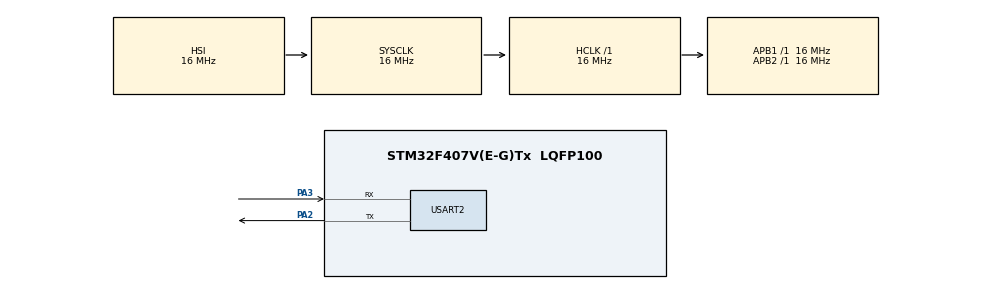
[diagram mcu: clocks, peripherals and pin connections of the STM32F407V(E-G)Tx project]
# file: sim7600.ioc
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FREERTOS.Tasks01=defaultTask,0,128,StartDefaultTask,Default,NULL,Dynamic,NULL,NULL
Mcu.Family=STM32F4
Mcu.Name=STM32F407V(E-G)Tx
Mcu.Package=LQFP100
NVIC.PriorityGroup=NVIC_PRIORITYGROUP_4
NVIC.TIM1_UP_TIM10_IRQn=true\:0\:0\:false\:false\:true\:false\:false\:true
NVIC.TimeBase=TIM1_UP_TIM10_IRQn
NVIC.TimeBaseIP=TIM1
NVIC.USART2_IRQn=true\:0\:0\:false\:false\:true\:false\:true\:true
PA13.Mode=Serial_Wire
PA13.Signal=SYS_JTMS-SWDIO
PA14.Mode=Serial_Wire
PA14.Signal=SYS_JTCK-SWCLK
PA2.Mode=Asynchronous
PA2.Signal=USART2_TX
PA3.Mode=Asynchronous
PA3.Signal=USART2_RX
PH0-OSC_IN.Mode=HSE-External-Oscillator
PH0-OSC_IN.Signal=RCC_OSC_IN
PH1-OSC_OUT.Mode=HSE-External-Oscillator
PH1-OSC_OUT.Signal=RCC_OSC_OUT
ProjectManager.HeapSize=0x200
ProjectManager.StackSize=0x400
ProjectManager.TargetToolchain=STM32CubeIDE
RCC.AHBFreq_Value=16000000
RCC.APB1Freq_Value=16000000
RCC.APB2Freq_Value=16000000
RCC.CortexFreq_Value=16000000
RCC.HSE_VALUE=25000000
RCC.HSI_VALUE=16000000
RCC.LSE_VALUE=32768
RCC.SYSCLKFreq_VALUE=16000000
RCC.VCOOutputFreq_Value=192000000
USART2.VirtualMode=VM_ASYNC
VP_FREERTOS_VS_CMSIS_V1.Mode=CMSIS_V1
VP_SYS_VS_tim1.Mode=TIM1
board=custom

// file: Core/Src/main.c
/* USER CODE BEGIN Header */
/**
  ******************************************************************************
  * @file           : main.c
  * @brief          : Main program body
  ******************************************************************************
  * @attention
  *
  * <h2><center>&copy; Copyright (c) 2021 STMicroelectronics.
  * All rights reserved.</center></h2>
  *
  * This software component is licensed by ST under BSD 3-Clause license,
  * the "License"; You may not use this file except in compliance with the
  * License. You may obtain a copy of the License at:
  *                        opensource.org/licenses/BSD-3-Clause
  *
  ******************************************************************************
  */
/* USER CODE END Header */
#include "main.h"
#include "cmsis_os.h"

UART_HandleTypeDef huart2;

osThreadId defaultTaskHandle;

void SystemClock_Config(void);
static void MX_GPIO_Init(void);
static void MX_USART2_UART_Init(void);
void StartDefaultTask(void const * argument);

int main(void)
{

  /* MCU Configuration--------------------------------------------------------*/

  /* Reset of all peripherals, Initializes the Flash interface and the Systick. */
  HAL_Init();

  /* Configure the system clock */
  SystemClock_Config();

  /* Initialize all configured peripherals */
  MX_GPIO_Init();
  MX_USART2_UART_Init();

  /* Create the thread(s) */
  /* definition and creation of defaultTask */
  __HAL_UART_ENABLE_IT(&huart2, UART_IT_RXNE);
  MX_FREERTOS_Init();

  /* Start scheduler */
  osKernelStart();

  /* We should never get here as control is now taken by the scheduler */
  /* Infinite loop */
  while (1)
  {

  }
}

void SystemClock_Config(void)
{
  RCC_OscInitTypeDef RCC_OscInitStruct = {0};
  RCC_ClkInitTypeDef RCC_ClkInitStruct = {0};

  /** Configure the main internal regulator output voltage
  */
  __HAL_RCC_PWR_CLK_ENABLE();
  __HAL_PWR_VOLTAGESCALING_CONFIG(PWR_REGULATOR_VOLTAGE_SCALE1);
  /** Initializes the RCC Oscillators according to the specified parameters
  * in the RCC_OscInitTypeDef structure.
  */
  RCC_OscInitStruct.OscillatorType = RCC_OSCILLATORTYPE_HSI;
  RCC_OscInitStruct.HSIState = RCC_HSI_ON;
  RCC_OscInitStruct.HSICalibrationValue = RCC_HSICALIBRATION_DEFAULT;
  RCC_OscInitStruct.PLL.PLLState = RCC_PLL_NONE;
  if (HAL_RCC_OscConfig(&RCC_OscInitStruct) != HAL_OK)
  {
    Error_Handler();
  }
  /** Initializes the CPU, AHB and APB buses clocks
  */
  RCC_ClkInitStruct.ClockType = RCC_CLOCKTYPE_HCLK|RCC_CLOCKTYPE_SYSCLK
                              |RCC_CLOCKTYPE_PCLK1|RCC_CLOCKTYPE_PCLK2;
  RCC_ClkInitStruct.SYSCLKSource = RCC_SYSCLKSOURCE_HSI;
  RCC_ClkInitStruct.AHBCLKDivider = RCC_SYSCLK_DIV1;
  RCC_ClkInitStruct.APB1CLKDivider = RCC_HCLK_DIV1;
  RCC_ClkInitStruct.APB2CLKDivider = RCC_HCLK_DIV1;

  if (HAL_RCC_ClockConfig(&RCC_ClkInitStruct, FLASH_LATENCY_0) != HAL_OK)
  {
    Error_Handler();
  }
}

static void MX_USART2_UART_Init(void)
{

  huart2.Instance = USART2;
  huart2.Init.BaudRate = 115200;
  huart2.Init.WordLength = UART_WORDLENGTH_8B;
  huart2.Init.StopBits = UART_STOPBITS_1;
  huart2.Init.Parity = UART_PARITY_NONE;
  huart2.Init.Mode = UART_MODE_TX_RX;
  huart2.Init.HwFlowCtl = UART_HWCONTROL_NONE;
  huart2.Init.OverSampling = UART_OVERSAMPLING_16;
  if (HAL_UART_Init(&huart2) != HAL_OK)
  {
    Error_Handler();
  }

}

static void MX_GPIO_Init(void)
{

  /* GPIO Ports Clock Enable */
  __HAL_RCC_GPIOH_CLK_ENABLE();
  __HAL_RCC_GPIOA_CLK_ENABLE();

}

void HAL_TIM_PeriodElapsedCallback(TIM_HandleTypeDef *htim)
{
  if (htim->Instance == TIM1) {
    HAL_IncTick();
  }
}

void Error_Handler(void)
{
}

/************************ (C) COPYRIGHT STMicroelectronics *****END OF FILE****/

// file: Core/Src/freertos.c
/* USER CODE BEGIN Header */
/**
  ******************************************************************************
  * File Name          : freertos.c
  * Description        : Code for freertos applications
  ******************************************************************************
  * @attention
  *
  * <h2><center>&copy; Copyright (c) 2021 STMicroelectronics.
  * All rights reserved.</center></h2>
  *
  * This software component is licensed by ST under Ultimate Liberty license
  * SLA0044, the "License"; You may not use this file except in compliance with
  * the License. You may obtain a copy of the License at:
  *                             www.st.com/SLA0044
  *
  ******************************************************************************
  */
/* USER CODE END Header */

#include "FreeRTOS.h"
#include "task.h"
#include "main.h"
#include "cmsis_os.h"
#include "stdint.h"
#include "stdio.h"
#include "command.h"
/* USER CODE BEGIN Includes */
extern uint32_t gotCommandFlag;
extern uint8_t commandBuffer[100];
extern uint32_t commandBufferIndex;
osMessageQId xQueueControlHandle;
osMessageQId xQueueMessageHandle;
osMessageQId xQueueDownlinkHandle;
osMessageQId xQueueUplinkHandle;
osMessageQId xQueueResetHandle;
/* USER CODE END Includes */
osThreadId netSIMTask;
/* USER CODE BEGIN PTD */
osThreadId defaultTaskHandle;
/* USER CODE END PTD */

/* USER CODE BEGIN PD */
void ResetHandlerTask(void *arg);
/* USER CODE END FunctionPrototypes */
extern void netsimTask(void const *arg);
void StartDefaultTask(void const * argument);
void MX_FREERTOS_Init(void);
/* USER CODE END PD */

/* GetIdleTaskMemory prototype (linked to static allocation support) */
void vApplicationGetIdleTaskMemory( StaticTask_t **ppxIdleTaskTCBBuffer, StackType_t **ppxIdleTaskStackBuffer, uint32_t *pulIdleTaskStackSize );

/* USER CODE BEGIN GET_IDLE_TASK_MEMORY */
static StaticTask_t xIdleTaskTCBBuffer;
static StackType_t xIdleStack[configMINIMAL_STACK_SIZE];

void vApplicationGetIdleTaskMemory( StaticTask_t **ppxIdleTaskTCBBuffer, StackType_t **ppxIdleTaskStackBuffer, uint32_t *pulIdleTaskStackSize )
{
  *ppxIdleTaskTCBBuffer = &xIdleTaskTCBBuffer;
  *ppxIdleTaskStackBuffer = &xIdleStack[0];
  *pulIdleTaskStackSize = configMINIMAL_STACK_SIZE;
  /* place for user code */
}
/* USER CODE END GET_IDLE_TASK_MEMORY */

/* USER CODE BEGIN Application */
void MX_FREERTOS_Init(void) {
  /* USER CODE BEGIN Init */

  /* USER CODE END Init */

  /* USER CODE BEGIN RTOS_MUTEX */
	/* add mutexes, ... */
  /* USER CODE END RTOS_MUTEX */

  /* Create the semaphores(s) */
  /* definition and creation of netMqttIpSemaphore */

  /* USER CODE BEGIN RTOS_SEMAPHORES */
	/* add semaphores, ... */
  /* USER CODE END RTOS_SEMAPHORES */

  /* Create the timer(s) */
  /* definition and creation of myTimer01 */
  /* USER CODE BEGIN RTOS_TIMERS */
	/* start timers, add new ones, ... */
  /* USER CODE END RTOS_TIMERS */

  /* USER CODE BEGIN RTOS_QUEUES */
	/* add queues, ... */

	osMessageQDef(xQueueControl, 1, xQueueControl_t);
	xQueueControlHandle = osMessageCreate(osMessageQ(xQueueControl), NULL);

	osMessageQDef(xQueueMessage, 1, uint8_t);
	xQueueMessageHandle = osMessageCreate(osMessageQ(xQueueMessage), NULL);

	osMessageQDef(xQueueDownlink, 1, xQueueMbMqtt_t);
	xQueueDownlinkHandle = osMessageCreate(osMessageQ(xQueueDownlink), NULL);

	osMessageQDef(xQueueUplink, 1, xQueueMbMqtt_t);
	xQueueUplinkHandle = osMessageCreate(osMessageQ(xQueueUplink), NULL);

	osMessageQDef(xQueueReset, 1, sizeof(uint32_t));
	xQueueResetHandle = osMessageCreate(osMessageQ(xQueueUplink), NULL);

  /* USER CODE END RTOS_QUEUES */

  /* Create the thread(s) */
  /* definition and creation of defaultTask */
  osThreadDef(defaultTask, StartDefaultTask, osPriorityNormal, 0, 512);
  defaultTaskHandle = osThreadCreate(osThread(defaultTask), NULL);
}
  /* USER CODE BEGIN RTOS_THREADS */
	/* add threads, ... */
 void StartDefaultTask(void const * argument)
  {
    /* USER CODE BEGIN StartDefaultTask */
  	/*Create Task Modules in this line*/
  	/*SIm serive*/
  	osThreadDef(netSIMTask, netsimTask, osPriorityNormal, 0, 4 * 128);
  	netSIMTask = osThreadCreate(osThread(netSIMTask), NULL);
  	printf("\r\n MemFree: %d", xPortGetFreeHeapSize());

  	/*Controller*/
  	xQueueControl_t xQueueControl;
  	#define PORT_DEFAULT_DELAY	1000
  	uint8_t uiSysState = SYS_START;
  	uint8_t uiSysUpdate = FALSE;
  	BaseType_t sysError;
  	/* Infinite loop */
  	for (;;) {
  		switch (uiSysState) {
  		case SYS_START:
  			//printf("\r\n Task Controller: Implementing...  \r\n");
  			uiSysUpdate = TRUE;
  			uiSysState++;
  			break;
  		case SYS_SIM_TASK:
  			//printf("\r\n Starting netMQTTTask module:  \r\n");
  			sysError = xQueueReceive(xQueueControlHandle, &xQueueControl,portMAX_DELAY);
  			if (sysError == pdTRUE) {
  				if ((xQueueControl.xState == TASK_RUNNING) && (xQueueControl.xTask == netSIMTask)) {
  					//printf("\r\n Starting netMQTTTask module: OK \r\n");
  					uiSysUpdate = TRUE;
  					uiSysState++;
  				}
  			} else {
  					uiSysUpdate = TRUE;
  					uiSysState++;
  			}
  			break;
  		case SYS_DEFAULT:
  			if (gotCommandFlag) {
  				gotCommandFlag = 0;
  				memset(commandBuffer,'\0',sizeof(commandBuffer));
  			}
  			osDelay(10);
  			break;

  		}
  		if ((uiSysUpdate == TRUE) && (uiSysState != SYS_DEFAULT)) {
  			xQueueSend(xQueueMessageHandle, &uiSysState, 0);
  			uiSysUpdate = FALSE;
  		}
  //		osDelay(200);
  	}
    /* USER CODE END StartDefaultTask */
  }
  /* USER CODE END RTOS_THREADS */

/* USER CODE END Application */

/************************ (C) COPYRIGHT STMicroelectronics *****END OF FILE****/
